# STM32WBA5Mxx register map
File version: 1.0
Registers are 32-bit, read-write, reset 0x0 unless marked. A register's access mark holds for its fields unless they carry their own. Offsets are from the block's base; [hi:lo] are bit positions; {n}, {i} and the like mark numbered series; 'fields as' and 'values as' point back to an identical list.

## RAMCFG
Base 0x40026000
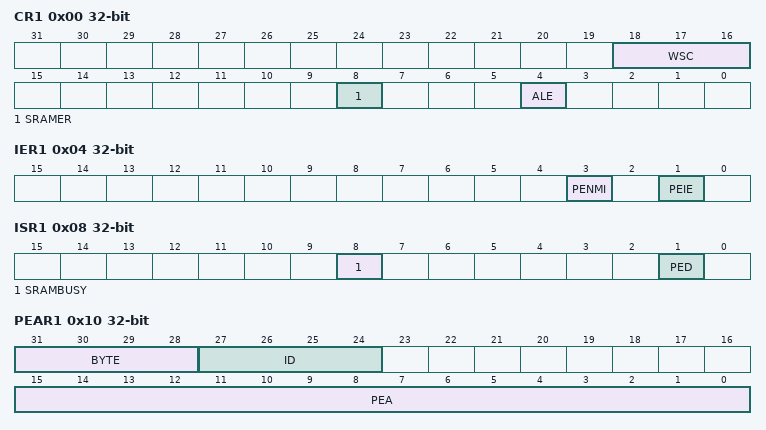
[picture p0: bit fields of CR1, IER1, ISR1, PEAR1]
0x00 CR1 — Control Register
  [18:16] WSC — WSC[18:16] Wait State Configuration field
  [8] SRAMER — Start Erase
  [4] ALE — Address Latching Enable
0x04 IER1 — Interrupt enable register
  [3] PENMI — Parity error NMI
  [1] PEIE — Parity error interrupt enable
0x08 ISR1 — Interrupt status register
  [8] SRAMBUSY — SRAM busy with erase operation
  [1] PED — Parity error detected
0x10 PEAR1 — Parity error address register
  [31:28] BYTE — Byte parity error flag
  [27:24] ID — Parity error AHB bus master ID
  [15:0] PEA — Parity error SRAM word aligned address offset
0x14 ICR1 — Interrupt clear register
  [1] CPED — Clear parity error detect bit
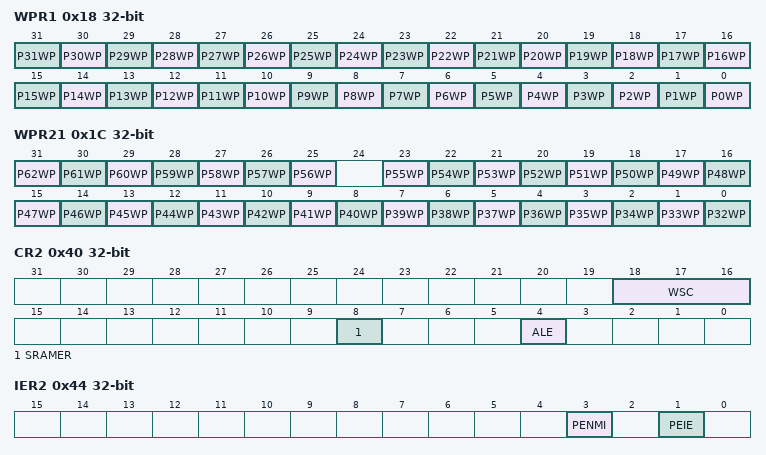
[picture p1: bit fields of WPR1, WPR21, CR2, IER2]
0x18 WPR1 — Write protection register 1
  [n] P{n}WP (n=0..31) — Write Protection Page {n:02}
0x1C WPR21 — Write protection register 2
  [n-31] P{n}WP (n=56..62) — Write Protection Page {n}
  [n-32] P{n}WP (n=32..55) — Write Protection Page {n}
0x28 ERKEYR1 — Erase key register
  [7:0] ERASEKEY — Erase write protection key
0x40 CR2 — Control Register
  fields as CR1
0x44 IER2 — Interrupt enable register
  fields as IER1
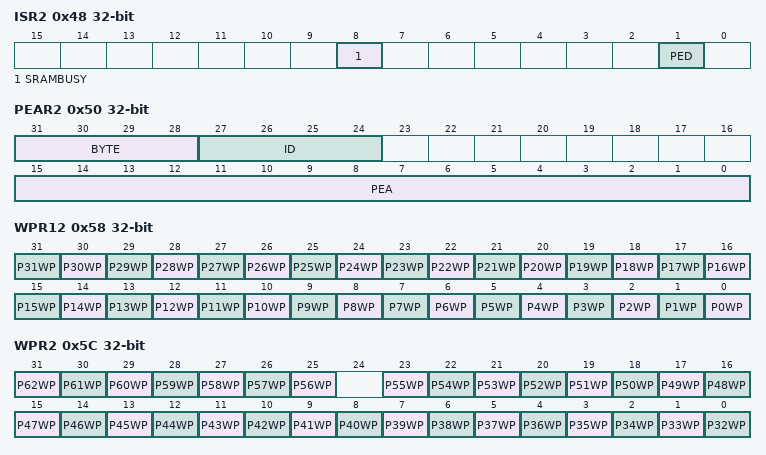
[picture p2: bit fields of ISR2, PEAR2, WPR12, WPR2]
0x48 ISR2 — Interrupt status register
  fields as ISR1
0x50 PEAR2 — Parity error address register
  fields as PEAR1
0x54 ICR2 — Interrupt clear register
  [1] CPED — Clear parity error detect bit
0x58 WPR12 — Write protection register 1
  [n] P{n}WP (n=0..31) — Write Protection Page {n:02}
0x5C WPR2 — Write protection register 2
  fields as WPR21
0x68 ERKEYR2 — Erase key register
  [7:0] ERASEKEY — Erase write protection key
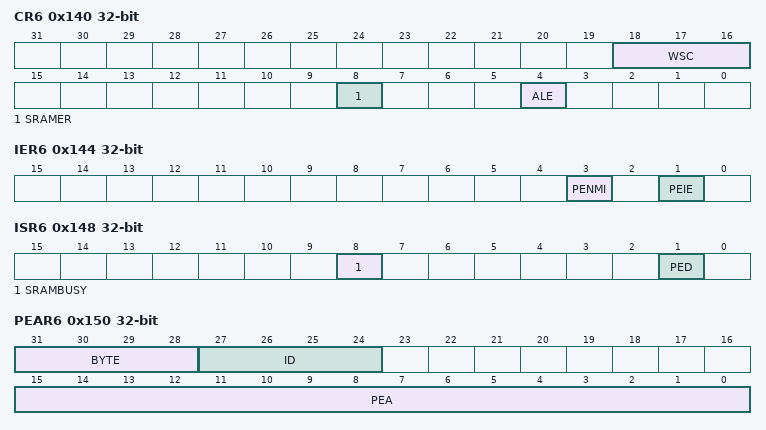
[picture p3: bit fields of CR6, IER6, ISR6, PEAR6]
0x140 CR6 — Control Register
  fields as CR1
0x144 IER6 — Interrupt enable register
  fields as IER1
0x148 ISR6 — Interrupt status register
  fields as ISR1
0x150 PEAR6 — Parity error address register
  fields as PEAR1
0x154 ICR6 — Interrupt clear register
  [1] CPED — Clear parity error detect bit
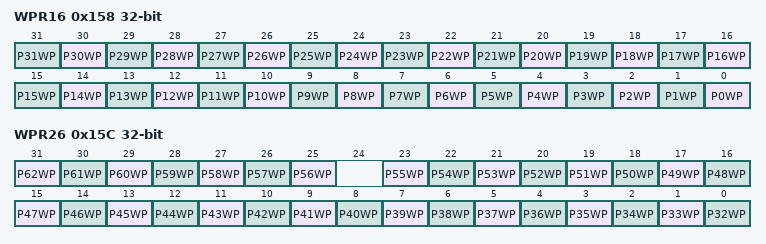
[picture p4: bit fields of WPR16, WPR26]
0x158 WPR16 — Write protection register 1
  [n] P{n}WP (n=0..31) — Write Protection Page {n:02}
0x15C WPR26 — Write protection register 2
  fields as WPR21
0x168 ERKEYR6 — Erase key register
  [7:0] ERASEKEY — Erase write protection key

## ICACHE — Instruction Cache
Base 0x40030400
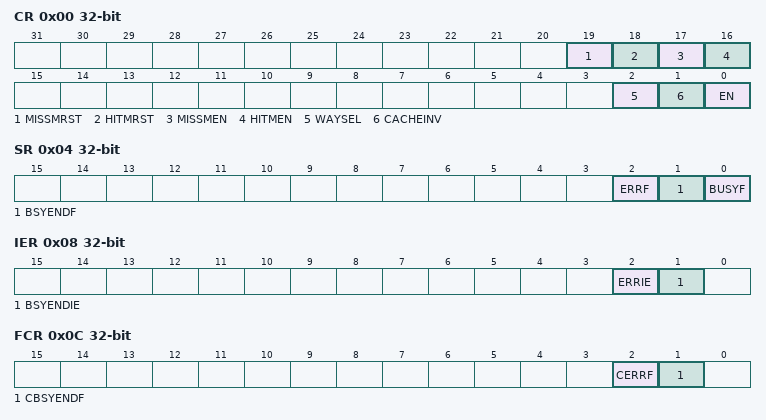
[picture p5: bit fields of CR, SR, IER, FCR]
0x00 CR — ICACHE control register
  [19] MISSMRST — Miss monitor reset
  [18] HITMRST — Hit monitor reset
  [17] MISSMEN — Miss monitor enable
  [16] HITMEN — Hit monitor enable
  [2] WAYSEL — Ways selection
    0=ICACHE_1WAY (1-way cache (direct mapped cache)); 1=ICACHE_2WAYS (2-ways set associative cache (default))
  [1] CACHEINV — Cache invalidation
  [0] EN — Enable
0x04 SR — ICACHE status register
  [2] ERRF — Cache error flag
  [1] BSYENDF — Busy end flag
  [0] BUSYF — Busy flag
0x08 IER — ICACHE interrupt enable register
  [2] ERRIE — Cache error interrupt enable
  [1] BSYENDIE — Busy end interrupt enable
0x0C FCR — ICACHE Flag clear register
  [2] CERRF — Cache error flag clear
  [1] CBSYENDF — Busy end flag clear
0x10 HMONR — ICACHE hit monitor register
  [31:0] HITMON — Cache hit monitor register
0x14 MMONR — ICACHE miss monitor register
  [15:0] MISSMON — Cache miss monitor register
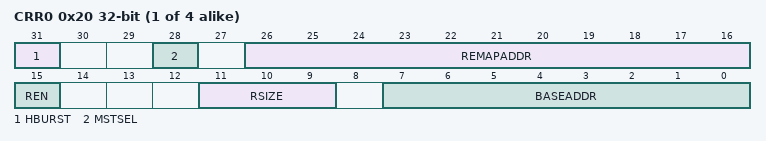
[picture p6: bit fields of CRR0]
{0x20+4i} CRR{i} (i=0..3) — ICACHE region {i} configuration register
  [31] HBURST — Region X output burst type
  [28] MSTSEL — Region X AHB cache master selection
  [26:16] REMAPADDR — Remap address of Region X to be remapped
  [15] REN — Region X enable
  [11:9] RSIZE — Region X size
  [7:0] BASEADDR — Base address of region X to remap

## GTZC_TZSC — Global TrustZone Controller
Base 0x40032400
0x00 CR — TZSC control register
  [0] LCK — GTZC Secure and privilege configurations lock
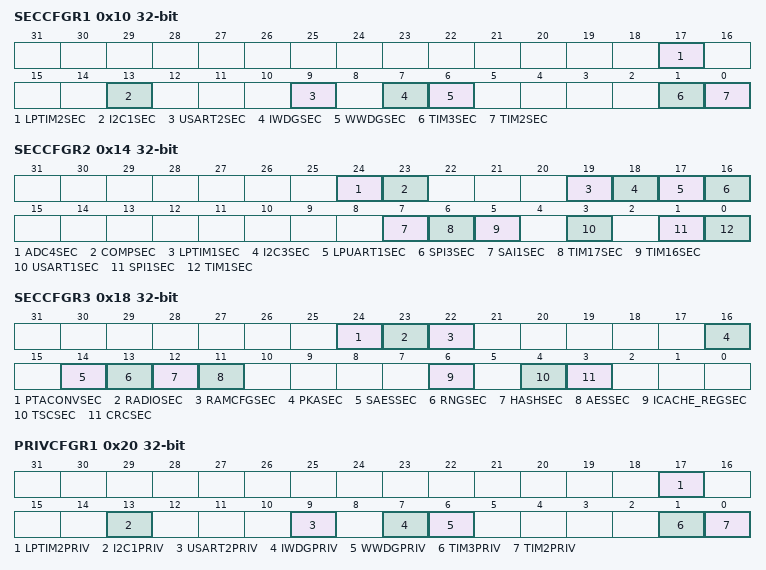
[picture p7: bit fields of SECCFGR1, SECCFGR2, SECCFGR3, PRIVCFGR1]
0x10 SECCFGR1 — TZSC secure configuration register 1
  [17] LPTIM2SEC — secure access mode for LPTIM2
  [13] I2C1SEC — secure access mode for I2C1
  [9] USART2SEC — secure access mode for USART2
  [7] IWDGSEC — secure access mode for IWDG
  [6] WWDGSEC — secure access mode for WWDG
  [1] TIM3SEC — secure access mode for TIM3
  [0] TIM2SEC — secure access mode for TIM2
0x14 SECCFGR2 — TZSC secure configuration register 2
  [24] ADC4SEC — secure access mode for ADC4
  [23] COMPSEC — secure access mode for COMP
  [19] LPTIM1SEC — secure access mode for LPTIM1
  [18] I2C3SEC — secure access mode for I2C3
  [17] LPUART1SEC — secure access mode for LPUART1
  [16] SPI3SEC — secure access mode for SPI3
  [7] SAI1SEC — secure access mode for SAI1
  [6] TIM17SEC — secure access mode for TIM17
  [5] TIM16SEC — secure access mode for TIM16
  [3] USART1SEC — secure access mode for USART1
  [1] SPI1SEC — secure access mode for SPI1
  [0] TIM1SEC — secure access mode for TIM1
0x18 SECCFGR3 — TZSC secure configuration register 3
  [24] PTACONVSEC — secure access mode for PTACONV
  [23] RADIOSEC — secure access mode for 2.4 GHz RADIO
  [22] RAMCFGSEC — secure access mode for RAMCFG
  [16] PKASEC — secure access mode for PKA
  [14] SAESSEC — secure access mode for SAES
  [13] RNGSEC — secure access mode for RNG
  [12] HASHSEC — secure access mode for HASH
  [11] AESSEC — secure access mode for AES
  [6] ICACHE_REGSEC — secure access mode for ICACHE_REG
  [4] TSCSEC — secure access mode for TSC
  [3] CRCSEC — secure access mode for CRC
0x20 PRIVCFGR1 — TZSC privilege configuration register 1
  [17] LPTIM2PRIV — privileged access mode for LPTIM2
  [13] I2C1PRIV — privileged access mode for I2C1
  [9] USART2PRIV — privileged access mode for USART2
  [7] IWDGPRIV — privileged access mode for IWDG
  [6] WWDGPRIV — privileged access mode for WWDG
  [1] TIM3PRIV — privileged access mode for TIM3
  [0] TIM2PRIV — privileged access mode for TIM2
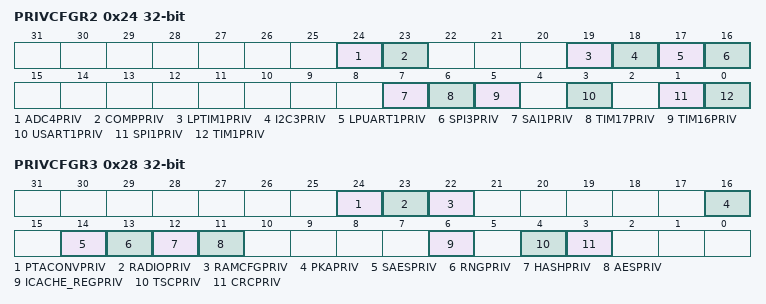
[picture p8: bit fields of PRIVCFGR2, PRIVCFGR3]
0x24 PRIVCFGR2 — TZSC privilege configuration register 2
  [24] ADC4PRIV — privileged access mode for ADC4
  [23] COMPPRIV — privileged access mode for COMP
  [19] LPTIM1PRIV — privileged access mode for LPTIM1
  [18] I2C3PRIV — privileged access mode for I2C3
  [17] LPUART1PRIV — privileged access mode for LPUART1
  [16] SPI3PRIV — privileged access mode for SPI3
  [7] SAI1PRIV — privileged access mode for SAI1
  [6] TIM17PRIV — privileged access mode for TIM17
  [5] TIM16PRIV — privileged access mode for TIM16
  [3] USART1PRIV — privileged access mode for USART1
  [1] SPI1PRIV — privileged access mode for SPI1
  [0] TIM1PRIV — privileged access mode for TIM1
0x28 PRIVCFGR3 — TZSC privilege configuration register 3
  [24] PTACONVPRIV — privileged access mode for PTACONV
  [23] RADIOPRIV — privileged access mode for 2.4 GHz RADIO
  [22] RAMCFGPRIV — privileged access mode for RAMCFG
  [16] PKAPRIV — privileged access mode for PKA
  [14] SAESPRIV — privileged access mode for SAES
  [13] RNGPRIV — privileged access mode for RNG
  [12] HASHPRIV — privileged access mode for HASH
  [11] AESPRIV — privileged access mode for AES
  [6] ICACHE_REGPRIV — privileged access mode for ICACHE_REG
  [4] TSCPRIV — privileged access mode for TSC
  [3] CRCPRIV — privileged access mode for CRC
